# ATmega32HVBrevB register map
Vendor: Atmel; File version: 1.0
CPU: other r0p0, little endian, no MPU, no FPU, 4 interrupt priority bits
Registers are 8-bit, read-write, reset 0x0 unless marked. A register's access mark holds for its fields unless they carry their own. Offsets are from the block's base; [hi:lo] are bit positions; {n}, {i} and the like mark numbered series.

## EEPROM
Base 0x0080003F
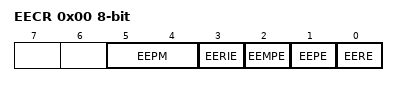
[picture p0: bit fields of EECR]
0x00 EECR — EEPROM Control Register
  [5:4] EEPM
    0=ERASE_AND_WRITE_IN_ONE_OPERATION; 1=ERASE_ONLY; 2=WRITE_ONLY
  [3] EERIE — EEProm Ready Interrupt Enable
  [2] EEMPE — EEPROM Master Write Enable
  [1] EEPE — EEPROM Write Enable
  [0] EERE — EEPROM Read Enable
0x01 EEDR — EEPROM Data Register
0x02 EEAR 16-bit (reset mask 0xFF) — EEPROM Read/Write Access

## EXINT — External Interrupts
Base 0x0080003B
0x00 PCIFR — Pin Change Interrupt Flag Register (read-only for debugger)
  [1:0] PCIF — Pin Change Interrupt Flags
0x01 EIFR — External Interrupt Flag Register (read-only for debugger)
  [3:0] INTF — External Interrupt Flags
0x02 EIMSK — External Interrupt Mask Register
  [3:0] INT — External Interrupt Request 3 Enable
0x2D PCICR — Pin Change Interrupt Control Register
  [1:0] PCIE — Pin Change Interrupt Enables
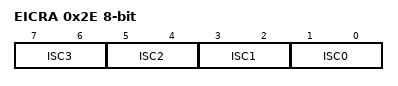
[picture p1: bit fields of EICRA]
0x2E EICRA — External Interrupt Control Register
  [all] fields
    0=LOW_LEVEL_OF_INTX; 1=ANY_LOGICAL_CHANGE_OF_INTX; 2=FALLING_EDGE_OF_INTX; 3=RISING_EDGE_OF_INTX
  [2n+1:2n] ISC{n} (n=0..3) — External Interrupt Sense Control {n} Bits
0x30 PCMSK0 — Pin Change Enable Mask Register 0
0x31 PCMSK1 — Pin Change Enable Mask Register 1

## FET — FET Control
Base 0x008000F0
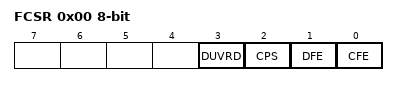
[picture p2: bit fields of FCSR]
0x00 FCSR — FET Control and Status Register
  [3] DUVRD — Deep Under-Voltage Recovery Disable
  [2] CPS — Current Protection Status
  [1] DFE — Discharge FET Enable
  [0] CFE — Charge FET Enable

## FUSE — Fuses
Base 0x00800000
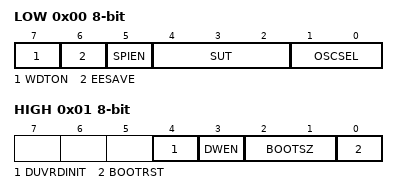
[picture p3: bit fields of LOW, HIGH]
0x00 LOW
  [7] WDTON — Watch-dog Timer always on
  [6] EESAVE — Preserve EEPROM through the Chip Erase cycle
  [5] SPIEN — Serial program downloading (SPI) enabled
  [4:2] SUT — Select start-up time
    0=14CK_4MS (Start-up time 14 CK + 4 ms); 1=14CK_8MS (Start-up time 14 CK + 8 ms); 2=14CK_16MS (Start-up time 14 CK + 16 ms); 3=14CK_32MS (Start-up time 14 CK + 32 ms); 4=14CK_64MS (Start-up time 14 CK + 64 ms); 5=14CK_128MS (Start-up time 14 CK + 128 ms); 6=14CK_256MS (Start-up time 14 CK + 256 ms); 7=14CK_512MS (Start-up time 14 CK + 512 ms)
  [1:0] OSCSEL — Oscillator select
    1=DEFAULT
0x01 HIGH
  [4] DUVRDINIT — DUVR mode on
  [3] DWEN — Debug Wire enable
  [2:1] BOOTSZ — Select Boot Size
    0=2048W_3800 (Boot Flash size=2048 words Boot address=$3800); 1=1024W_3C00 (Boot Flash size=1024 words Boot address=$3C00); 2=512W_3E00 (Boot Flash size=512 words Boot address=$3E00); 3=256W_3F00 (Boot Flash size=256 words Boot address=$3F00)
  [0] BOOTRST — Boot Reset vector Enabled

## LOCKBIT — Lockbits
Base 0x00800000
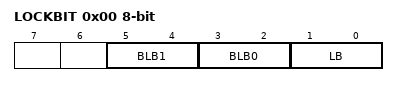
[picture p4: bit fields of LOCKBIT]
0x00 LOCKBIT
  [5:4] BLB1 — Boot Loader Protection Mode
    0=LPM_SPM_DISABLE (LPM and SPM prohibited in Boot Section); 1=LPM_DISABLE (LPM prohibited in Boot Section); 2=SPM_DISABLE (SPM prohibited in Boot Section); 3=NO_LOCK (No lock on SPM and LPM in Boot Section)
  [3:2] BLB0 — Boot Loader Protection Mode
    0=LPM_SPM_DISABLE (LPM and SPM prohibited in Application Section); 1=LPM_DISABLE (LPM prohibited in Application Section); 2=SPM_DISABLE (SPM prohibited in Application Section); 3=NO_LOCK (No lock on SPM and LPM in Application Section)
  [1:0] LB — Memory Lock
    0=PROG_VER_DISABLED (Further programming and verification disabled); 2=PROG_DISABLED (Further programming disabled); 3=NO_LOCK (No memory lock features enabled)

## PORTA — I/O Port
Base 0x00800020
0x00 PINA — Port A Input Pins (read-only for debugger)
0x01 DDRA — Port A Data Direction Register (read-only for debugger)
0x02 PORTA — Port A Data Register (read-only for debugger)

## PORTB — I/O Port
Base 0x00800023
0x00 PINB — Port B Input Pins (read-only for debugger)
0x01 DDRB — Port B Data Direction Register
0x02 PORTB — Port B Data Register
